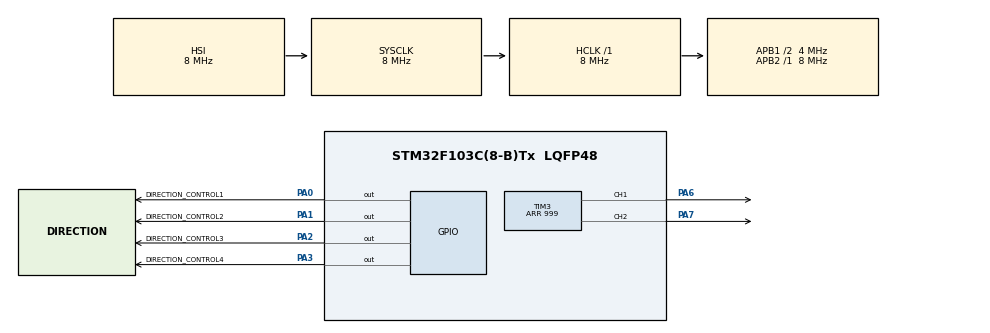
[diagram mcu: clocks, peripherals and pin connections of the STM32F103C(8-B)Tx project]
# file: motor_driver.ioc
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Mcu.Family=STM32F1
Mcu.Name=STM32F103C(8-B)Tx
Mcu.Package=LQFP48
NVIC.PriorityGroup=NVIC_PRIORITYGROUP_4
NVIC.TIM1_UP_IRQn=true\:15\:0\:false\:false\:true\:false\:true\:true
NVIC.TimeBase=TIM1_UP_IRQn
NVIC.TimeBaseIP=TIM1
PA0-WKUP.GPIO_Label=DIRECTION_CONTROL1
PA0-WKUP.Signal=GPIO_Output
PA1.GPIO_Label=DIRECTION_CONTROL2
PA1.Signal=GPIO_Output
PA13.Mode=Serial_Wire
PA13.Signal=SYS_JTMS-SWDIO
PA14.Mode=Serial_Wire
PA14.Signal=SYS_JTCK-SWCLK
PA2.GPIO_Label=DIRECTION_CONTROL3
PA2.Signal=GPIO_Output
PA3.GPIO_Label=DIRECTION_CONTROL4
PA3.Signal=GPIO_Output
PA6.GPIO_ModeDefaultPP=GPIO_MODE_AF_PP
PA6.GPIO_Speed=GPIO_SPEED_FREQ_LOW
PA6.Signal=S_TIM3_CH1
PA7.GPIO_ModeDefaultPP=GPIO_MODE_AF_PP
PA7.GPIO_Speed=GPIO_SPEED_FREQ_LOW
PA7.Signal=S_TIM3_CH2
ProjectManager.HeapSize=0x200
ProjectManager.StackSize=0x400
ProjectManager.TargetToolchain=CMake
RCC.AHBFreq_Value=8000000
RCC.APB1CLKDivider=RCC_HCLK_DIV2
RCC.APB1Freq_Value=4000000
RCC.APB1TimFreq_Value=8000000
RCC.APB2Freq_Value=8000000
RCC.APB2TimFreq_Value=8000000
RCC.HCLKFreq_Value=8000000
RCC.PLLMUL=RCC_PLL_MUL16
RCC.SYSCLKFreq_VALUE=8000000
RCC.USBFreq_Value=64000000
SH.S_TIM3_CH1.0=TIM3_CH1,PWM Generation1 CH1
SH.S_TIM3_CH2.0=TIM3_CH2,PWM Generation2 CH2
TIM3.Channel-PWM\ Generation1\ CH1=TIM_CHANNEL_1
TIM3.Channel-PWM\ Generation2\ CH2=TIM_CHANNEL_2
TIM3.Period=999
VP_SYS_VS_tim1.Mode=TIM1
VP_TIM3_VS_ClockSourceINT.Mode=Internal
board=custom

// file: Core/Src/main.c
/* USER CODE BEGIN Header */
/**
  ******************************************************************************
  * @file           : main.c
  * @brief          : Main program body
  ******************************************************************************
  * @attention
  *
  * Copyright (c) 2025 STMicroelectronics.
  * All rights reserved.
  *
  * This software is licensed under terms that can be found in the LICENSE file
  * in the root directory of this software component.
  * If no LICENSE file comes with this software, it is provided AS-IS.
  *
  ******************************************************************************
  */
/* USER CODE END Header */
#include "main.h"

TIM_HandleTypeDef htim3;

void SystemClock_Config(void);
static void MX_GPIO_Init(void);
static void MX_TIM3_Init(void);

int main(void)
{

  /* MCU Configuration--------------------------------------------------------*/

  /* Reset of all peripherals, Initializes the Flash interface and the Systick. */
  HAL_Init();

  /* Configure the system clock */
  SystemClock_Config();

  /* Initialize all configured peripherals */
  MX_GPIO_Init();
  MX_TIM3_Init();
  Motor_Init();
  /* Infinite loop */
  while (1)
  {

    /* USER CODE BEGIN 3 */
    MotorA_SetDirection(MOTOR_DIR_FORWARD);
    for(int i = 0; i < 100; i++) {
        MotorA_SetSpeed(i); // Gradually increase speed
        HAL_Delay(50); // Delay to observe speed change
      MotorA_SetSpeed(50); // Set Motor A to 50% speed
    }
  }
  /* USER CODE END 3 */
}

void SystemClock_Config(void)
{
  RCC_OscInitTypeDef RCC_OscInitStruct = {0};
  RCC_ClkInitTypeDef RCC_ClkInitStruct = {0};

  /** Initializes the RCC Oscillators according to the specified parameters
  * in the RCC_OscInitTypeDef structure.
  */
  RCC_OscInitStruct.OscillatorType = RCC_OSCILLATORTYPE_HSI;
  RCC_OscInitStruct.HSIState = RCC_HSI_ON;
  RCC_OscInitStruct.HSICalibrationValue = RCC_HSICALIBRATION_DEFAULT;
  RCC_OscInitStruct.PLL.PLLState = RCC_PLL_NONE;
  if (HAL_RCC_OscConfig(&RCC_OscInitStruct) != HAL_OK)
  {
    Error_Handler();
  }

  /** Initializes the CPU, AHB and APB buses clocks
  */
  RCC_ClkInitStruct.ClockType = RCC_CLOCKTYPE_HCLK|RCC_CLOCKTYPE_SYSCLK
                              |RCC_CLOCKTYPE_PCLK1|RCC_CLOCKTYPE_PCLK2;
  RCC_ClkInitStruct.SYSCLKSource = RCC_SYSCLKSOURCE_HSI;
  RCC_ClkInitStruct.AHBCLKDivider = RCC_SYSCLK_DIV1;
  RCC_ClkInitStruct.APB1CLKDivider = RCC_HCLK_DIV2;
  RCC_ClkInitStruct.APB2CLKDivider = RCC_HCLK_DIV1;

  if (HAL_RCC_ClockConfig(&RCC_ClkInitStruct, FLASH_LATENCY_0) != HAL_OK)
  {
    Error_Handler();
  }
}

static void MX_TIM3_Init(void)
{

  TIM_ClockConfigTypeDef sClockSourceConfig = {0};
  TIM_MasterConfigTypeDef sMasterConfig = {0};
  TIM_OC_InitTypeDef sConfigOC = {0};

  htim3.Instance = TIM3;
  htim3.Init.Prescaler = 0;
  htim3.Init.CounterMode = TIM_COUNTERMODE_UP;
  htim3.Init.Period = 999;
  htim3.Init.ClockDivision = TIM_CLOCKDIVISION_DIV1;
  htim3.Init.AutoReloadPreload = TIM_AUTORELOAD_PRELOAD_DISABLE;
  if (HAL_TIM_Base_Init(&htim3) != HAL_OK)
  {
    Error_Handler();
  }
  sClockSourceConfig.ClockSource = TIM_CLOCKSOURCE_INTERNAL;
  if (HAL_TIM_ConfigClockSource(&htim3, &sClockSourceConfig) != HAL_OK)
  {
    Error_Handler();
  }
  if (HAL_TIM_PWM_Init(&htim3) != HAL_OK)
  {
    Error_Handler();
  }
  sMasterConfig.MasterOutputTrigger = TIM_TRGO_RESET;
  sMasterConfig.MasterSlaveMode = TIM_MASTERSLAVEMODE_DISABLE;
  if (HAL_TIMEx_MasterConfigSynchronization(&htim3, &sMasterConfig) != HAL_OK)
  {
    Error_Handler();
  }
  sConfigOC.OCMode = TIM_OCMODE_PWM1;
  sConfigOC.Pulse = 0;
  sConfigOC.OCPolarity = TIM_OCPOLARITY_HIGH;
  sConfigOC.OCFastMode = TIM_OCFAST_DISABLE;
  if (HAL_TIM_PWM_ConfigChannel(&htim3, &sConfigOC, TIM_CHANNEL_1) != HAL_OK)
  {
    Error_Handler();
  }
  if (HAL_TIM_PWM_ConfigChannel(&htim3, &sConfigOC, TIM_CHANNEL_2) != HAL_OK)
  {
    Error_Handler();
  }
  HAL_TIM_MspPostInit(&htim3);

}

static void MX_GPIO_Init(void)
{
  GPIO_InitTypeDef GPIO_InitStruct = {0};

  /* GPIO Ports Clock Enable */
  __HAL_RCC_GPIOA_CLK_ENABLE();

  /*Configure GPIO pin Output Level */
  HAL_GPIO_WritePin(GPIOA, DIRECTION_CONTROL1_Pin|DIRECTION_CONTROL2_Pin|DIRECTION_CONTROL3_Pin|DIRECTION_CONTROL4_Pin, GPIO_PIN_RESET);

  /*Configure GPIO pins : DIRECTION_CONTROL1_Pin DIRECTION_CONTROL2_Pin DIRECTION_CONTROL3_Pin DIRECTION_CONTROL4_Pin */
  GPIO_InitStruct.Pin = DIRECTION_CONTROL1_Pin|DIRECTION_CONTROL2_Pin|DIRECTION_CONTROL3_Pin|DIRECTION_CONTROL4_Pin;
  GPIO_InitStruct.Mode = GPIO_MODE_OUTPUT_PP;
  GPIO_InitStruct.Pull = GPIO_NOPULL;
  GPIO_InitStruct.Speed = GPIO_SPEED_FREQ_LOW;
  HAL_GPIO_Init(GPIOA, &GPIO_InitStruct);

}

void HAL_TIM_PeriodElapsedCallback(TIM_HandleTypeDef *htim)
{
  if (htim->Instance == TIM1)
  {
    HAL_IncTick();
  }
}

void Error_Handler(void)
{
  __disable_irq();
  while (1)
  {
  }
}
